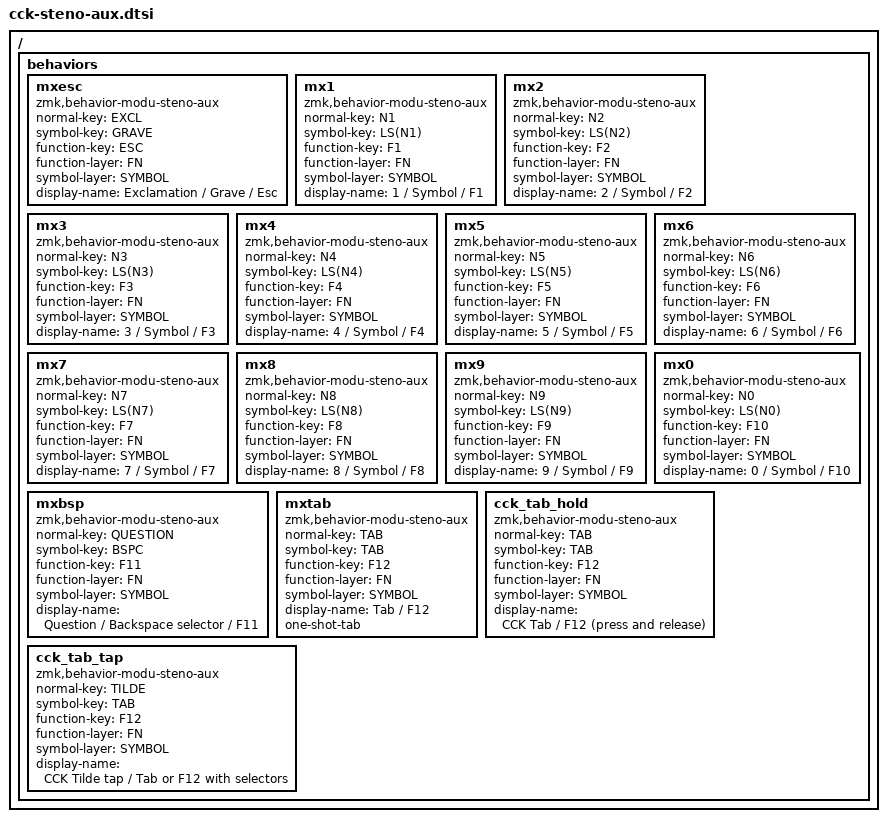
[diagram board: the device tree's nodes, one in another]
/* SPDX-License-Identifier: MIT */
/ { behaviors {
    mxesc: mxesc { compatible = "zmk,behavior-modu-steno-aux"; #binding-cells = <0>;
        normal-key = <EXCL>; symbol-key = <GRAVE>; function-key = <ESC>;
        function-layer = <FN>; symbol-layer = <SYMBOL>; display-name = "Exclamation / Grave / Esc";
    };
    mx1: mx1 { compatible = "zmk,behavior-modu-steno-aux"; #binding-cells = <0>;
        normal-key = <N1>; symbol-key = <LS(N1)>; function-key = <F1>;
        function-layer = <FN>; symbol-layer = <SYMBOL>; display-name = "1 / Symbol / F1";
    };
    mx2: mx2 { compatible = "zmk,behavior-modu-steno-aux"; #binding-cells = <0>;
        normal-key = <N2>; symbol-key = <LS(N2)>; function-key = <F2>;
        function-layer = <FN>; symbol-layer = <SYMBOL>; display-name = "2 / Symbol / F2";
    };
    mx3: mx3 { compatible = "zmk,behavior-modu-steno-aux"; #binding-cells = <0>;
        normal-key = <N3>; symbol-key = <LS(N3)>; function-key = <F3>;
        function-layer = <FN>; symbol-layer = <SYMBOL>; display-name = "3 / Symbol / F3";
    };
    mx4: mx4 { compatible = "zmk,behavior-modu-steno-aux"; #binding-cells = <0>;
        normal-key = <N4>; symbol-key = <LS(N4)>; function-key = <F4>;
        function-layer = <FN>; symbol-layer = <SYMBOL>; display-name = "4 / Symbol / F4";
    };
    mx5: mx5 { compatible = "zmk,behavior-modu-steno-aux"; #binding-cells = <0>;
        normal-key = <N5>; symbol-key = <LS(N5)>; function-key = <F5>;
        function-layer = <FN>; symbol-layer = <SYMBOL>; display-name = "5 / Symbol / F5";
    };
    mx6: mx6 { compatible = "zmk,behavior-modu-steno-aux"; #binding-cells = <0>;
        normal-key = <N6>; symbol-key = <LS(N6)>; function-key = <F6>;
        function-layer = <FN>; symbol-layer = <SYMBOL>; display-name = "6 / Symbol / F6";
    };
    mx7: mx7 { compatible = "zmk,behavior-modu-steno-aux"; #binding-cells = <0>;
        normal-key = <N7>; symbol-key = <LS(N7)>; function-key = <F7>;
        function-layer = <FN>; symbol-layer = <SYMBOL>; display-name = "7 / Symbol / F7";
    };
    mx8: mx8 { compatible = "zmk,behavior-modu-steno-aux"; #binding-cells = <0>;
        normal-key = <N8>; symbol-key = <LS(N8)>; function-key = <F8>;
        function-layer = <FN>; symbol-layer = <SYMBOL>; display-name = "8 / Symbol / F8";
    };
    mx9: mx9 { compatible = "zmk,behavior-modu-steno-aux"; #binding-cells = <0>;
        normal-key = <N9>; symbol-key = <LS(N9)>; function-key = <F9>;
        function-layer = <FN>; symbol-layer = <SYMBOL>; display-name = "9 / Symbol / F9";
    };
    mx0: mx0 { compatible = "zmk,behavior-modu-steno-aux"; #binding-cells = <0>;
        normal-key = <N0>; symbol-key = <LS(N0)>; function-key = <F10>;
        function-layer = <FN>; symbol-layer = <SYMBOL>; display-name = "0 / Symbol / F10";
    };
    mxbsp: mxbsp { compatible = "zmk,behavior-modu-steno-aux"; #binding-cells = <0>;
        normal-key = <QUESTION>; symbol-key = <BSPC>; function-key = <F11>;
        function-layer = <FN>; symbol-layer = <SYMBOL>; display-name = "Question / Backspace selector / F11";
    };
    mxtab: mxtab { compatible = "zmk,behavior-modu-steno-aux"; #binding-cells = <0>;
        normal-key = <TAB>; symbol-key = <TAB>; function-key = <F12>;
        function-layer = <FN>; symbol-layer = <SYMBOL>; display-name = "Tab / F12";
        one-shot-tab;
    };
    cck_tab_hold: cck_tab_hold {
        compatible = "zmk,behavior-modu-steno-aux"; #binding-cells = <0>;
        normal-key = <TAB>; symbol-key = <TAB>; function-key = <F12>;
        function-layer = <FN>; symbol-layer = <SYMBOL>;
        display-name = "CCK Tab / F12 (press and release)";
    };
    cck_tab_tap: cck_tab_tap {
        compatible = "zmk,behavior-modu-steno-aux"; #binding-cells = <0>;
        normal-key = <TILDE>; symbol-key = <TAB>; function-key = <F12>;
        function-layer = <FN>; symbol-layer = <SYMBOL>;
        display-name = "CCK Tilde tap / Tab or F12 with selectors";
    };
}; };
